AUTOSAR XML (schema 4-1-3)
standard types defined: boolean, uint16, uint8
package /UAES/ASW/CompuMethods
  compu method CM_boolean: 0=FALSE, 1=TRUE
package /UAES/ASW/DataConstrs
  range DC_boolean: raw 0..1
  range DC_uint16: raw 0..65535
  range DC_uint8: raw 0..255
package /UAES/ASW/DataTypeMappingSets
  data type mapping set DTMS_Lock_ComCnvRx
package /UAES/ASW/PortInterfaces
  36 x sender receiver interface:
    ComRx_bBCS_VehSpdVD: invalidation-policy{data-element=ComRx_bBCS_VehSpdVD/Val, handle-invalid=DONT-INVALIDATE}
      data Val: sw-calibration-access=READ-ONLY, type=boolean
    ComRx_bLCK_FillerCapLock_Alock: invalidation-policy{data-element=ComRx_bLCK_FillerCapLock_Alock/Val, handle-invalid=DONT-INVALIDATE}
      data Val: sw-calibration-access=READ-ONLY, type=boolean
    ComRx_bLCK_FillerCapLock_Block: invalidation-policy{data-element=ComRx_bLCK_FillerCapLock_Block/Val, handle-invalid=DONT-INVALIDATE}
      data Val: sw-calibration-access=READ-ONLY, type=boolean
    ComRx_bLCK_PowerFillerCap: invalidation-policy{data-element=ComRx_bLCK_PowerFillerCap/Val, handle-invalid=DONT-INVALIDATE}
      data Val: sw-calibration-access=READ-ONLY, type=boolean
    ComRx_bLCK_RearLeftChildSaftyLock: invalidation-policy{data-element=ComRx_bLCK_RearLeftChildSaftyLock/Val, handle-invalid=DONT-INVALIDATE}
      data Val: sw-calibration-access=READ-ONLY, type=boolean
    ComRx_bLCK_RearLeftDoorLock: invalidation-policy{data-element=ComRx_bLCK_RearLeftDoorLock/Val, handle-invalid=DONT-INVALIDATE}
      data Val: sw-calibration-access=READ-ONLY, type=boolean
    ComRx_bLCK_RearLeftPowerDoor: invalidation-policy{data-element=ComRx_bLCK_RearLeftPowerDoor/Val, handle-invalid=DONT-INVALIDATE}
      data Val: sw-calibration-access=READ-ONLY, type=boolean
    ComRx_bLCK_RearRightChildSaftyLock: invalidation-policy{data-element=ComRx_bLCK_RearRightChildSaftyLock/Val, handle-invalid=DONT-INVALIDATE}
      data Val: sw-calibration-access=READ-ONLY, type=boolean
    ComRx_bLCK_RearRightDoorLock: invalidation-policy{data-element=ComRx_bLCK_RearRightDoorLock/Val, handle-invalid=DONT-INVALIDATE}
      data Val: sw-calibration-access=READ-ONLY, type=boolean
    ComRx_bLCK_RearRightPowerDoor: invalidation-policy{data-element=ComRx_bLCK_RearRightPowerDoor/Val, handle-invalid=DONT-INVALIDATE}
      data Val: sw-calibration-access=READ-ONLY, type=boolean
    ComRx_bLCK_TrunkLock: invalidation-policy{data-element=ComRx_bLCK_TrunkLock/Val, handle-invalid=DONT-INVALIDATE}
      data Val: sw-calibration-access=READ-ONLY, type=boolean
    ComRx_u16BCS_VehSpd: invalidation-policy{data-element=ComRx_u16BCS_VehSpd/Val, handle-invalid=DONT-INVALIDATE}
      data Val: sw-calibration-access=READ-ONLY, type=uint16
    ComRx_u8LCK_FillerCapCommandActionType: invalidation-policy{data-element=ComRx_u8LCK_FillerCapCommandActionType/Val, handle-invalid=DONT-INVALIDATE}
      data Val: sw-calibration-access=READ-ONLY, type=uint8
    ComRx_u8LCK_LockCommandActionType: invalidation-policy{data-element=ComRx_u8LCK_LockCommandActionType/Val, handle-invalid=DONT-INVALIDATE}
      data Val: sw-calibration-access=READ-ONLY, type=uint8
    ComRx_u8LCK_PowerDoorCommandActionType: invalidation-policy{data-element=ComRx_u8LCK_PowerDoorCommandActionType/Val, handle-invalid=DONT-INVALIDATE}
      data Val: sw-calibration-access=READ-ONLY, type=uint8
    ComRx_u8SRS_CrashOutputSt: invalidation-policy{data-element=ComRx_u8SRS_CrashOutputSt/Val, handle-invalid=DONT-INVALIDATE}
      data Val: sw-calibration-access=READ-ONLY, type=uint8
    ComRx_u8VCU_CrntGearLvl_A02: invalidation-policy{data-element=ComRx_u8VCU_CrntGearLvl_A02/Val, handle-invalid=DONT-INVALIDATE}
      data Val: sw-calibration-access=READ-ONLY, type=uint8
    ComRx_u8VCU_CrntGearLvl_A09: invalidation-policy{data-element=ComRx_u8VCU_CrntGearLvl_A09/Val, handle-invalid=DONT-INVALIDATE}
      data Val: sw-calibration-access=READ-ONLY, type=uint8
    gCAN_bBCS_VehSpdVD: invalidation-policy{data-element=gCAN_bBCS_VehSpdVD/Val, handle-invalid=DONT-INVALIDATE}
      data Val: sw-calibration-access=READ-ONLY, type=boolean
    gCAN_bLCK_FillerCapLock_Alock: invalidation-policy{data-element=gCAN_bLCK_FillerCapLock_Alock/Val, handle-invalid=DONT-INVALIDATE}
      data Val: sw-calibration-access=READ-ONLY, type=boolean
    gCAN_bLCK_FillerCapLock_Block: invalidation-policy{data-element=gCAN_bLCK_FillerCapLock_Block/Val, handle-invalid=DONT-INVALIDATE}
      data Val: sw-calibration-access=READ-ONLY, type=boolean
    gCAN_bLCK_PowerFillerCap: invalidation-policy{data-element=gCAN_bLCK_PowerFillerCap/Val, handle-invalid=DONT-INVALIDATE}
      data Val: sw-calibration-access=READ-ONLY, type=boolean
    gCAN_bLCK_RearLeftChildSaftyLock: invalidation-policy{data-element=gCAN_bLCK_RearLeftChildSaftyLock/Val, handle-invalid=DONT-INVALIDATE}
      data Val: sw-calibration-access=READ-ONLY, type=boolean
    gCAN_bLCK_RearLeftDoorLock: invalidation-policy{data-element=gCAN_bLCK_RearLeftDoorLock/Val, handle-invalid=DONT-INVALIDATE}
      data Val: sw-calibration-access=READ-ONLY, type=boolean
    gCAN_bLCK_RearLeftPowerDoor: invalidation-policy{data-element=gCAN_bLCK_RearLeftPowerDoor/Val, handle-invalid=DONT-INVALIDATE}
      data Val: sw-calibration-access=READ-ONLY, type=boolean
    gCAN_bLCK_RearRightChildSaftyLock: invalidation-policy{data-element=gCAN_bLCK_RearRightChildSaftyLock/Val, handle-invalid=DONT-INVALIDATE}
      data Val: sw-calibration-access=READ-ONLY, type=boolean
    gCAN_bLCK_RearRightDoorLock: invalidation-policy{data-element=gCAN_bLCK_RearRightDoorLock/Val, handle-invalid=DONT-INVALIDATE}
      data Val: sw-calibration-access=READ-ONLY, type=boolean
    gCAN_bLCK_RearRightPowerDoor: invalidation-policy{data-element=gCAN_bLCK_RearRightPowerDoor/Val, handle-invalid=DONT-INVALIDATE}
      data Val: sw-calibration-access=READ-ONLY, type=boolean
    gCAN_bLCK_TrunkLock: invalidation-policy{data-element=gCAN_bLCK_TrunkLock/Val, handle-invalid=DONT-INVALIDATE}
      data Val: sw-calibration-access=READ-ONLY, type=boolean
    gCAN_u16BCS_VehSpd: invalidation-policy{data-element=gCAN_u16BCS_VehSpd/Val, handle-invalid=DONT-INVALIDATE}
      data Val: sw-calibration-access=READ-ONLY, type=uint16
    gCAN_u8LCK_FillerCapCommandActionType: invalidation-policy{data-element=gCAN_u8LCK_FillerCapCommandActionType/Val, handle-invalid=DONT-INVALIDATE}
      data Val: sw-calibration-access=READ-ONLY, type=uint8
    gCAN_u8LCK_LockCommandActionType: invalidation-policy{data-element=gCAN_u8LCK_LockCommandActionType/Val, handle-invalid=DONT-INVALIDATE}
      data Val: sw-calibration-access=READ-ONLY, type=uint8
    gCAN_u8LCK_PowerDoorCommandActionType: invalidation-policy{data-element=gCAN_u8LCK_PowerDoorCommandActionType/Val, handle-invalid=DONT-INVALIDATE}
      data Val: sw-calibration-access=READ-ONLY, type=uint8
    gCAN_u8SRS_CrashOutputSt: invalidation-policy{data-element=gCAN_u8SRS_CrashOutputSt/Val, handle-invalid=DONT-INVALIDATE}
      data Val: sw-calibration-access=READ-ONLY, type=uint8
    gCAN_u8VCU_CrntGearLvl_A02: invalidation-policy{data-element=gCAN_u8VCU_CrntGearLvl_A02/Val, handle-invalid=DONT-INVALIDATE}
      data Val: sw-calibration-access=READ-ONLY, type=uint8
    gCAN_u8VCU_CrntGearLvl_A09: invalidation-policy{data-element=gCAN_u8VCU_CrntGearLvl_A09/Val, handle-invalid=DONT-INVALIDATE}
      data Val: sw-calibration-access=READ-ONLY, type=uint8
package /UAES/ASW/SwComponentTypes
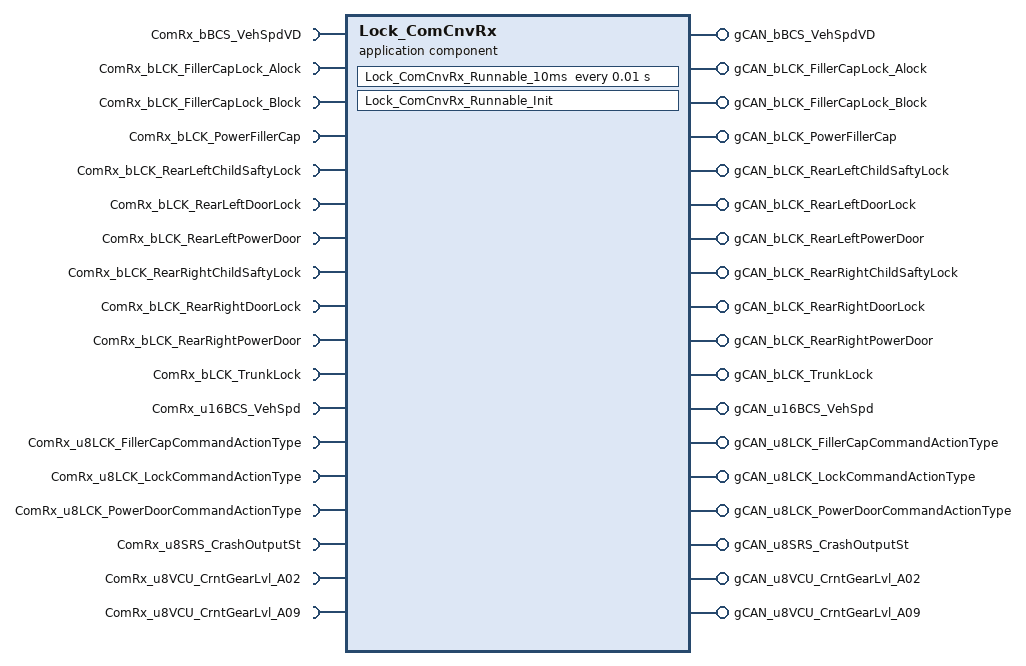
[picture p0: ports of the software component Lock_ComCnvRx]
  application sw component type Lock_ComCnvRx
    18 x provide port:
      gCAN_bBCS_VehSpdVD: nonqueued-sender-com-spec{data-element=gCAN_bBCS_VehSpdVD/Val, init-value=0}, provided-interface=gCAN_bBCS_VehSpdVD
      gCAN_bLCK_FillerCapLock_Alock: nonqueued-sender-com-spec{data-element=gCAN_bLCK_FillerCapLock_Alock/Val, init-value=0}, provided-interface=gCAN_bLCK_FillerCapLock_Alock
      gCAN_bLCK_FillerCapLock_Block: nonqueued-sender-com-spec{data-element=gCAN_bLCK_FillerCapLock_Block/Val, init-value=0}, provided-interface=gCAN_bLCK_FillerCapLock_Block
      gCAN_bLCK_PowerFillerCap: nonqueued-sender-com-spec{data-element=gCAN_bLCK_PowerFillerCap/Val, init-value=0}, provided-interface=gCAN_bLCK_PowerFillerCap
      gCAN_bLCK_RearLeftChildSaftyLock: nonqueued-sender-com-spec{data-element=gCAN_bLCK_RearLeftChildSaftyLock/Val, init-value=0}, provided-interface=gCAN_bLCK_RearLeftChildSaftyLock
      gCAN_bLCK_RearLeftDoorLock: nonqueued-sender-com-spec{data-element=gCAN_bLCK_RearLeftDoorLock/Val, init-value=0}, provided-interface=gCAN_bLCK_RearLeftDoorLock
      gCAN_bLCK_RearLeftPowerDoor: nonqueued-sender-com-spec{data-element=gCAN_bLCK_RearLeftPowerDoor/Val, init-value=0}, provided-interface=gCAN_bLCK_RearLeftPowerDoor
      gCAN_bLCK_RearRightChildSaftyLock: nonqueued-sender-com-spec{data-element=gCAN_bLCK_RearRightChildSaftyLock/Val, init-value=0}, provided-interface=gCAN_bLCK_RearRightChildSaftyLock
      gCAN_bLCK_RearRightDoorLock: nonqueued-sender-com-spec{data-element=gCAN_bLCK_RearRightDoorLock/Val, init-value=0}, provided-interface=gCAN_bLCK_RearRightDoorLock
      gCAN_bLCK_RearRightPowerDoor: nonqueued-sender-com-spec{data-element=gCAN_bLCK_RearRightPowerDoor/Val, init-value=0}, provided-interface=gCAN_bLCK_RearRightPowerDoor
      gCAN_bLCK_TrunkLock: nonqueued-sender-com-spec{data-element=gCAN_bLCK_TrunkLock/Val, init-value=0}, provided-interface=gCAN_bLCK_TrunkLock
      gCAN_u16BCS_VehSpd: nonqueued-sender-com-spec{data-element=gCAN_u16BCS_VehSpd/Val, init-value=0}, provided-interface=gCAN_u16BCS_VehSpd
      gCAN_u8LCK_FillerCapCommandActionType: nonqueued-sender-com-spec{data-element=gCAN_u8LCK_FillerCapCommandActionType/Val, init-value=0}, provided-interface=gCAN_u8LCK_FillerCapCommandActionType
      gCAN_u8LCK_LockCommandActionType: nonqueued-sender-com-spec{data-element=gCAN_u8LCK_LockCommandActionType/Val, init-value=0}, provided-interface=gCAN_u8LCK_LockCommandActionType
      gCAN_u8LCK_PowerDoorCommandActionType: nonqueued-sender-com-spec{data-element=gCAN_u8LCK_PowerDoorCommandActionType/Val, init-value=0}, provided-interface=gCAN_u8LCK_PowerDoorCommandActionType
      gCAN_u8SRS_CrashOutputSt: nonqueued-sender-com-spec{data-element=gCAN_u8SRS_CrashOutputSt/Val, init-value=0}, provided-interface=gCAN_u8SRS_CrashOutputSt
      gCAN_u8VCU_CrntGearLvl_A02: nonqueued-sender-com-spec{data-element=gCAN_u8VCU_CrntGearLvl_A02/Val, init-value=0}, provided-interface=gCAN_u8VCU_CrntGearLvl_A02
      gCAN_u8VCU_CrntGearLvl_A09: nonqueued-sender-com-spec{data-element=gCAN_u8VCU_CrntGearLvl_A09/Val, init-value=0}, provided-interface=gCAN_u8VCU_CrntGearLvl_A09
    18 x require port:
      ComRx_bBCS_VehSpdVD: nonqueued-receiver-com-spec{data-element=ComRx_bBCS_VehSpdVD/Val, filter=data-filter-type=ALWAYS, init-value=0}, required-interface=ComRx_bBCS_VehSpdVD
      ComRx_bLCK_FillerCapLock_Alock: nonqueued-receiver-com-spec{data-element=ComRx_bLCK_FillerCapLock_Alock/Val, filter=data-filter-type=ALWAYS, init-value=0}, required-interface=ComRx_bLCK_FillerCapLock_Alock
      ComRx_bLCK_FillerCapLock_Block: nonqueued-receiver-com-spec{data-element=ComRx_bLCK_FillerCapLock_Block/Val, filter=data-filter-type=ALWAYS, init-value=0}, required-interface=ComRx_bLCK_FillerCapLock_Block
      ComRx_bLCK_PowerFillerCap: nonqueued-receiver-com-spec{data-element=ComRx_bLCK_PowerFillerCap/Val, filter=data-filter-type=ALWAYS, init-value=0}, required-interface=ComRx_bLCK_PowerFillerCap
      ComRx_bLCK_RearLeftChildSaftyLock: nonqueued-receiver-com-spec{data-element=ComRx_bLCK_RearLeftChildSaftyLock/Val, filter=data-filter-type=ALWAYS, init-value=0}, required-interface=ComRx_bLCK_RearLeftChildSaftyLock
      ComRx_bLCK_RearLeftDoorLock: nonqueued-receiver-com-spec{data-element=ComRx_bLCK_RearLeftDoorLock/Val, filter=data-filter-type=ALWAYS, init-value=0}, required-interface=ComRx_bLCK_RearLeftDoorLock
      ComRx_bLCK_RearLeftPowerDoor: nonqueued-receiver-com-spec{data-element=ComRx_bLCK_RearLeftPowerDoor/Val, filter=data-filter-type=ALWAYS, init-value=0}, required-interface=ComRx_bLCK_RearLeftPowerDoor
      ComRx_bLCK_RearRightChildSaftyLock: nonqueued-receiver-com-spec{data-element=ComRx_bLCK_RearRightChildSaftyLock/Val, filter=data-filter-type=ALWAYS, init-value=0}, required-interface=ComRx_bLCK_RearRightChildSaftyLock
      ComRx_bLCK_RearRightDoorLock: nonqueued-receiver-com-spec{data-element=ComRx_bLCK_RearRightDoorLock/Val, filter=data-filter-type=ALWAYS, init-value=0}, required-interface=ComRx_bLCK_RearRightDoorLock
      ComRx_bLCK_RearRightPowerDoor: nonqueued-receiver-com-spec{data-element=ComRx_bLCK_RearRightPowerDoor/Val, filter=data-filter-type=ALWAYS, init-value=0}, required-interface=ComRx_bLCK_RearRightPowerDoor
      ComRx_bLCK_TrunkLock: nonqueued-receiver-com-spec{data-element=ComRx_bLCK_TrunkLock/Val, filter=data-filter-type=ALWAYS, init-value=0}, required-interface=ComRx_bLCK_TrunkLock
      ComRx_u16BCS_VehSpd: nonqueued-receiver-com-spec{data-element=ComRx_u16BCS_VehSpd/Val, filter=data-filter-type=ALWAYS, init-value=0}, required-interface=ComRx_u16BCS_VehSpd
      ComRx_u8LCK_FillerCapCommandActionType: nonqueued-receiver-com-spec{data-element=ComRx_u8LCK_FillerCapCommandActionType/Val, filter=data-filter-type=ALWAYS, init-value=0}, required-interface=ComRx_u8LCK_FillerCapCommandActionType
      ComRx_u8LCK_LockCommandActionType: nonqueued-receiver-com-spec{data-element=ComRx_u8LCK_LockCommandActionType/Val, filter=data-filter-type=ALWAYS, init-value=0}, required-interface=ComRx_u8LCK_LockCommandActionType
      ComRx_u8LCK_PowerDoorCommandActionType: nonqueued-receiver-com-spec{data-element=ComRx_u8LCK_PowerDoorCommandActionType/Val, filter=data-filter-type=ALWAYS, init-value=0}, required-interface=ComRx_u8LCK_PowerDoorCommandActionType
      ComRx_u8SRS_CrashOutputSt: nonqueued-receiver-com-spec{data-element=ComRx_u8SRS_CrashOutputSt/Val, filter=data-filter-type=ALWAYS, init-value=0}, required-interface=ComRx_u8SRS_CrashOutputSt
      ComRx_u8VCU_CrntGearLvl_A02: nonqueued-receiver-com-spec{data-element=ComRx_u8VCU_CrntGearLvl_A02/Val, filter=data-filter-type=ALWAYS, init-value=0}, required-interface=ComRx_u8VCU_CrntGearLvl_A02
      ComRx_u8VCU_CrntGearLvl_A09: nonqueued-receiver-com-spec{data-element=ComRx_u8VCU_CrntGearLvl_A09/Val, filter=data-filter-type=ALWAYS, init-value=0}, required-interface=ComRx_u8VCU_CrntGearLvl_A09
    behavior Lock_ComCnvRx_InternalBehavior: data-type-mapping=DTMS_Lock_ComCnvRx
      timing event TMT_Lock_ComCnvRx_Runnable_10ms: start-on-event=Lock_ComCnvRx_Runnable_10ms, period=0.01
      init event Lock_ComCnvRx_InitEvent: start-on-event=Lock_ComCnvRx_Runnable_Init
      runnable Lock_ComCnvRx_Runnable_10ms
        data-receive-point-by-arguments:
          18 x access:
            REC_ComRx_bBCS_VehSpdVD_Val: accessed-variable=ComRx_bBCS_VehSpdVD.Val
            REC_ComRx_bLCK_FillerCapLock_Alock_Val: accessed-variable=ComRx_bLCK_FillerCapLock_Alock.Val
            REC_ComRx_bLCK_FillerCapLock_Block_Val: accessed-variable=ComRx_bLCK_FillerCapLock_Block.Val
            REC_ComRx_bLCK_PowerFillerCap_Val: accessed-variable=ComRx_bLCK_PowerFillerCap.Val
            REC_ComRx_bLCK_RearLeftChildSaftyLock_Val: accessed-variable=ComRx_bLCK_RearLeftChildSaftyLock.Val
            REC_ComRx_bLCK_RearLeftDoorLock_Val: accessed-variable=ComRx_bLCK_RearLeftDoorLock.Val
            REC_ComRx_bLCK_RearLeftPowerDoor_Val: accessed-variable=ComRx_bLCK_RearLeftPowerDoor.Val
            REC_ComRx_bLCK_RearRightChildSaftyLock_Val: accessed-variable=ComRx_bLCK_RearRightChildSaftyLock.Val
            REC_ComRx_bLCK_RearRightDoorLock_Val: accessed-variable=ComRx_bLCK_RearRightDoorLock.Val
            REC_ComRx_bLCK_RearRightPowerDoor_Val: accessed-variable=ComRx_bLCK_RearRightPowerDoor.Val
            REC_ComRx_bLCK_TrunkLock_Val: accessed-variable=ComRx_bLCK_TrunkLock.Val
            REC_ComRx_u16BCS_VehSpd_Val: accessed-variable=ComRx_u16BCS_VehSpd.Val
            REC_ComRx_u8LCK_FillerCapCommandActionType_Val: accessed-variable=ComRx_u8LCK_FillerCapCommandActionType.Val
            REC_ComRx_u8LCK_LockCommandActionType_Val: accessed-variable=ComRx_u8LCK_LockCommandActionType.Val
            REC_ComRx_u8LCK_PowerDoorCommandActionType_Val: accessed-variable=ComRx_u8LCK_PowerDoorCommandActionType.Val
            REC_ComRx_u8SRS_CrashOutputSt_Val: accessed-variable=ComRx_u8SRS_CrashOutputSt.Val
            REC_ComRx_u8VCU_CrntGearLvl_A02_Val: accessed-variable=ComRx_u8VCU_CrntGearLvl_A02.Val
            REC_ComRx_u8VCU_CrntGearLvl_A09_Val: accessed-variable=ComRx_u8VCU_CrntGearLvl_A09.Val
        data-send-points:
          18 x access:
            SEND_gCAN_bBCS_VehSpdVD_Val: accessed-variable=gCAN_bBCS_VehSpdVD.Val
            SEND_gCAN_bLCK_FillerCapLock_Alock_Val: accessed-variable=gCAN_bLCK_FillerCapLock_Alock.Val
            SEND_gCAN_bLCK_FillerCapLock_Block_Val: accessed-variable=gCAN_bLCK_FillerCapLock_Block.Val
            SEND_gCAN_bLCK_PowerFillerCap_Val: accessed-variable=gCAN_bLCK_PowerFillerCap.Val
            SEND_gCAN_bLCK_RearLeftChildSaftyLock_Val: accessed-variable=gCAN_bLCK_RearLeftChildSaftyLock.Val
            SEND_gCAN_bLCK_RearLeftDoorLock_Val: accessed-variable=gCAN_bLCK_RearLeftDoorLock.Val
            SEND_gCAN_bLCK_RearLeftPowerDoor_Val: accessed-variable=gCAN_bLCK_RearLeftPowerDoor.Val
            SEND_gCAN_bLCK_RearRightChildSaftyLock_Val: accessed-variable=gCAN_bLCK_RearRightChildSaftyLock.Val
            SEND_gCAN_bLCK_RearRightDoorLock_Val: accessed-variable=gCAN_bLCK_RearRightDoorLock.Val
            SEND_gCAN_bLCK_RearRightPowerDoor_Val: accessed-variable=gCAN_bLCK_RearRightPowerDoor.Val
            SEND_gCAN_bLCK_TrunkLock_Val: accessed-variable=gCAN_bLCK_TrunkLock.Val
            SEND_gCAN_u16BCS_VehSpd_Val: accessed-variable=gCAN_u16BCS_VehSpd.Val
            SEND_gCAN_u8LCK_FillerCapCommandActionType_Val: accessed-variable=gCAN_u8LCK_FillerCapCommandActionType.Val
            SEND_gCAN_u8LCK_LockCommandActionType_Val: accessed-variable=gCAN_u8LCK_LockCommandActionType.Val
            SEND_gCAN_u8LCK_PowerDoorCommandActionType_Val: accessed-variable=gCAN_u8LCK_PowerDoorCommandActionType.Val
            SEND_gCAN_u8SRS_CrashOutputSt_Val: accessed-variable=gCAN_u8SRS_CrashOutputSt.Val
            SEND_gCAN_u8VCU_CrntGearLvl_A02_Val: accessed-variable=gCAN_u8VCU_CrntGearLvl_A02.Val
            SEND_gCAN_u8VCU_CrntGearLvl_A09_Val: accessed-variable=gCAN_u8VCU_CrntGearLvl_A09.Val
      runnable Lock_ComCnvRx_Runnable_Init
  swc implementation Lock_ComCnvRx_Implementation: behavior=Lock_ComCnvRx_InternalBehavior
    code-descriptors:
      code Default: artifact-descriptors=autosar-engineering-object={short-label=Default, category=SWSRC}
package /UAES/ASW/Units
  unit NoUnit: factor-si-to-unit=1, offset-si-to-unit=0
